# SAMA7D65D2GN8 register map
Vendor: Microchip Technology; Series: SAMA7D6; File version: 0
Registers are 32-bit, read-write, reset 0x0 unless marked. A register's access mark holds for its fields unless they carry their own. Offsets are from the block's base; [hi:lo] are bit positions; {n}, {i} and the like mark numbered series; 'fields as' and 'values as' point back to an identical list.

## SECUMOD — Security Module
Base 0xE0004000
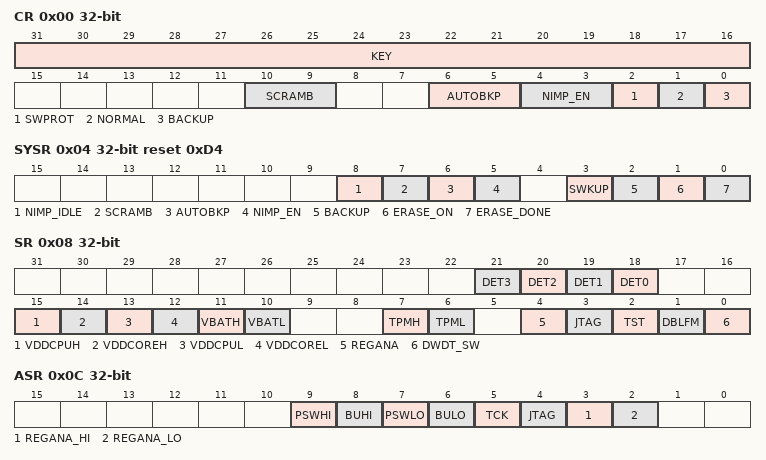
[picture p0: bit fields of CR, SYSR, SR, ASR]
0x00 CR wo — Control Register
  [31:16] KEY — Password
  [10:9] SCRAMB — Memory Scrambling Enable
    1=SCRAMB (Memories are scrambled (default).); 2=NO_SCRAMB (Memories are not scrambled.)
  [6:5] AUTOBKP — Automatic Normal to Backup Mode Switching
    1=AUTO_BCKP (When in Normal mode, the power-down of the core supply automatically switches to Backup mode simultaneously with core to backup isolation barrier activation (default).); 2=SW_BCKP (When in Normal mode, the software must switch to Backup mode before powering down the core.)
  [4:3] NIMP_EN — Non-Imprinting
    1=EN_NIMP (The non-imprinting mechanism is authorized to start when core power is off or bus reset is asserted); 2=DISABLED (The non-imprinting mechanism is disabled (default)); 3=EN_NIMP_IDLE (The non-imprinting mechanism is authorized to start when core power is off or bus reset is asserted or the CPU is idle)
  [2] SWPROT — Software Protection
    0=No effect; 1=Starts the BUSRAM4KB and BUREG256b Clear content
  [1] NORMAL — Normal Mode
    0=No effect; 1=Switches to Normal mode
  [0] BACKUP — Backup Mode
    0=No effect; 1=Switches to Backup mode
0x04 SYSR reset 0xD4 — System Status Register
  [8] NIMP_IDLE — 'CPU in Idle' Preliminary Condition for Non-Imprinting (RO)
    0=Idle is not part of the preliminary conditions list; 1=Idle is part of the preliminary conditions list
  [7] SCRAMB — Scrambling Enabled (RO)
    0=Disabled; 1=Enabled
  [6] AUTOBKP — Automatic Backup Mode Enabled (RO)
    0=Disabled; 1=Enabled
  [5] NIMP_EN — Non-Imprinting Enabled (RO)
    0=Disabled; 1=Enabled
  [3] SWKUP — SWKUP State (RO)
    0=No SWKUP signal sent since the last clear; 1=SWKUP signal has been sent since the last clear
  [2] BACKUP — Backup Mode (RO)
    0=Normal mode active; 1=Backup mode active
  [1] ERASE_ON — Erase Process Ongoing (RO)
    0=Erase automaton is not running; 1=Erase automaton is currently running, memories are not accessible
  [0] ERASE_DONE — Erasable Memories State (RW)
    0=Content of the secure memories has not been erased since the last clear; 1=Content of the secure memories has been erased since the last clear. Write a '1' to this bit to clear this flag. The flag also activates the SECURAM interrupt line as long as it is not cleared.
0x08 SR ro — Status Register
  [n+18] DET{n} (n=0..3) — PIOBUx Intrusion Detector
  [15] VDDCPUH — High VDDCPU Voltage Monitor
  [14] VDDCOREH — High VDDCORE Voltage Monitor
  [13] VDDCPUL — Low VDDCPU Voltage Monitor
  [12] VDDCOREL — Low VDDCORE Voltage Monitor
  [11] VBATH — High VBAT Voltage Monitor
  [10] VBATL — Low VBAT Voltage Monitor
  [7] TPMH — High Temperature Monitor
  [6] TPML — Low Temperature Monitor
  [4] REGANA — VDDANA Regulator Monitor
  [3] JTAG — Pins Monitor
  [2] TST — Test Pin Monitor
  [1] DBLFM — Double Frequency Monitor
  [0] DWDT_SW — Programmable Secure Watchdog Alarm
0x0C ASR ro — Auxiliary Status Register
  [9] PSWHI — VDDIN33 (used as secondary LDO power source through backup power switch) low alarm detected is the cause of VBATL flag in SECUMOD_SR
  [8] BUHI — VBAT high alarm detected is the cause of VBATH flag in SECUMOD_SR
  [7] PSWLO — VDDIN33 (used as secondary LDO power source through backup power switch) low alarm detected is the cause of VBATL flag in SECUMOD_SR
  [6] BULO — VBAT low alarm detected is the cause of VBATL flag in SECUMOD_SR
  [5] TCK — TCK/TMS activity detected is the cause of JTAG flag in SECUMOD_SR
  [4] JTAG — JTAGSEL or processor debug acknowledge is the cause of JTAG flag in SECUMOD_SR
  [3] REGANA_HI — High voltage alarm from VDDANA regulator is the cause of REGANA flag in SECUMOD_SR
  [2] REGANA_LO — Low voltage alarm from VDDANA regulator is the cause of REGANA flag in SECUMOD_SR
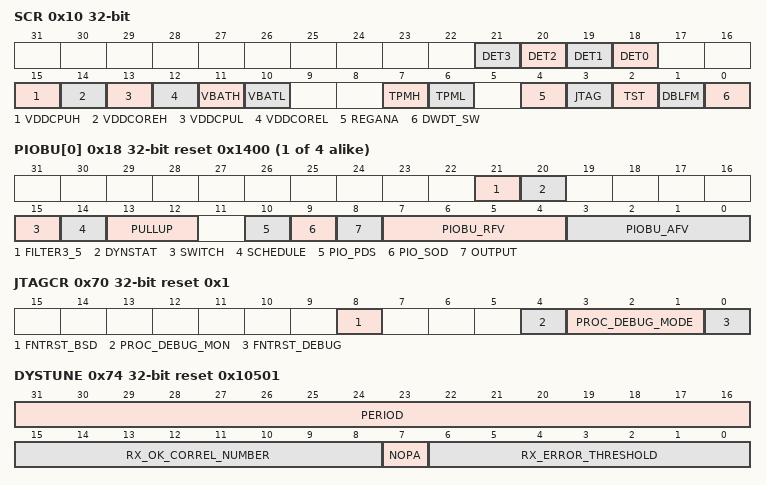
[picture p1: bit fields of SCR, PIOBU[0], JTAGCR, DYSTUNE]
0x10 SCR wo — Status Clear Register
  [n+18] DET{n} (n=0..3) — PIOBUx Intrusion Detector
  [15] VDDCPUH — High VDDCPU Voltage Monitor
  [14] VDDCOREH — High VDDCORE Voltage Monitor
  [13] VDDCPUL — Low VDDCPU Voltage Monitor
  [12] VDDCOREL — Low VDDCORE Voltage Monitor
  [11] VBATH — High VBAT Voltage Monitor
  [10] VBATL — Low VBAT Voltage Monitor
  [7] TPMH — High Temperature Monitor
  [6] TPML — Low Temperature Monitor
  [4] REGANA — VDDANA Regulator Monitor
  [3] JTAG — JTAG Pins Monitor
  [2] TST — Test Pin Monitor
  [1] DBLFM — Double Frequency Monitor
  [0] DWDT_SW — Programmable Secure Watchdog Alarm
0x14 RAMRDY ro — RAM Access Ready Register
  [0] READY — Ready for System Access Flag
{0x18+4i} PIOBU[{i}] (i=0..3) reset 0x1400 — PIO Backup Register x
  [21] FILTER3_5 — Filter for Dynamic Signatures Input
    0=3-stage majority vote (default); 1=5-stage majority vote
  [20] DYNSTAT — Switch for Static or Dynamic Detection Intrusion
    0=Static detection intrusion (default); 1=Dynamic detection intrusion
  [15] SWITCH — Switch State for Intrusion Detection
    0=Input default state is low level; 1=Input default state is high level
  [14] SCHEDULE — Pull-up/Down Scheduled
    0=Pull-up/pull-down is not scheduled; 1=Pull-up/pull-down is scheduled
  [13:12] PULLUP — Programmable Pull-up State
  [10] PIO_PDS — Level on the Pin in Input Mode (OUTPUT = 0) (Read-only)
    0=The I/O line is at level 0; 1=The I/O line is at level 1
  [9] PIO_SOD — Set/Clear the I/O Line when configured in Output Mode (OUTPUT =1)
    0=Clears the data to be driven on the I/O line; 1=Sets the data to be driven on the I/O line
  [8] OUTPUT — Configure I/O Line in Input/Output
    0=INPUT (I/O line is a pure input.); 1=OUTPUT (The I/O line is enabled in output.)
  [7:4] PIOBU_RFV — PIOBUx Reset Filter Value
    0=NO (0 (No static protection)); 1=MAX_2 (Maximum Counter Value: 2); 2=MAX_4 (Maximum Counter Value: 4); 3=MAX_8 (Maximum Counter Value: 8); 4=MAX_16 (Maximum Counter Value: 16); 5=MAX_32 (Maximum Counter Value: 32); 6=MAX_64 (Maximum Counter Value: 64); 7=MAX_128 (Maximum Counter Value: 128); 8=MAX_256 (Maximum Counter Value: 256); 9=MAX_512 (Maximum Counter Value: 512)
  [3:0] PIOBU_AFV — PIOBU Alarm Filter Value
    0=NO (0 (No static protection)); 1=MAX_2 (Maximum Counter Value before alarm: 2); 2=MAX_4 (Maximum Counter Value before alarm:4); 3=MAX_8 (Maximum Counter Value before alarm:8); 4=MAX_16 (Maximum Counter Value before alarm:16); 5=MAX_32 (Maximum Counter Value before alarm:32); 6=MAX_64 (Maximum Counter Value before alarm:64); 7=MAX_128 (Maximum Counter Value before alarm:128); 8=MAX_256 (Maximum Counter Value before alarm:256); 9=MAX_512 (Maximum Counter Value before alarm:512)
0x58 VBUFR reset 0x7 — VBAT Filter Register
  [2:0] VBATFV — VBAT Filter Value
0x64 VCOREFR reset 0x1FFF — VDDCORE Filter Register
  [12:0] VDDCORE_DBTV — VDDCORE Programmable Debouncing Time Value
0x68 VCPUFR reset 0x1FFF — VDDCPU Filter Register
  [12:0] VDDCPU_DBTV — VDDCPU Programmable Debouncing Time Value
0x70 JTAGCR reset 0x1 — JTAG Protection Control Register
  [8] FNTRST_BSD — Force Boundary JTAG NTRST
    0=Boundary JTAG are not blocked by the SECUMOD; 1=Boundary JTAG reset are held low, preventing Boundary JTAG to work
  [4] PROC_DEBUG_MON — Debug Acknowledge (DBGACK) Monitoring
    0=The Arm processor pin DBGACK is not monitored; as a consequence, the software can access debug features of the processor without causing an intrusion in the SECUMOD; 1=The Arm processor pin DBGACK is monitored. Processor entering in Debug mode triggers an intrusion
  [3:1] PROC_DEBUG_MODE — Invasive/Non-Invasive Secure/Non-Secure Debug Permissions
  [0] FNTRST_DEBUG — Force ARM Processor's TAP NTRST
    0=The ARM processor's TAP controller access is not blocked by the SECUMOD; 1=NDBGRESET of the ARM processor's TAP controller is held low, preventing the processor to switch to debug state
0x74 DYSTUNE reset 0x10501 — Dynamic Signature Tuning Register
  [31:16] PERIOD — Signature Clock Period
  [15:8] RX_OK_CORREL_NUMBER — Error Counter Reset Threshold
  [7] NOPA — No Periodic Alarm
    0=The alarm is regenerated periodically while intrusion is maintained; 1=The alarm is not regenerated periodically while intrusion is maintained
  [6:0] RX_ERROR_THRESHOLD — Error Detection Threshold
0x78 SCRKEY — Scrambling Key Register
  [31:0] SCRKEY — Scrambling Key Value
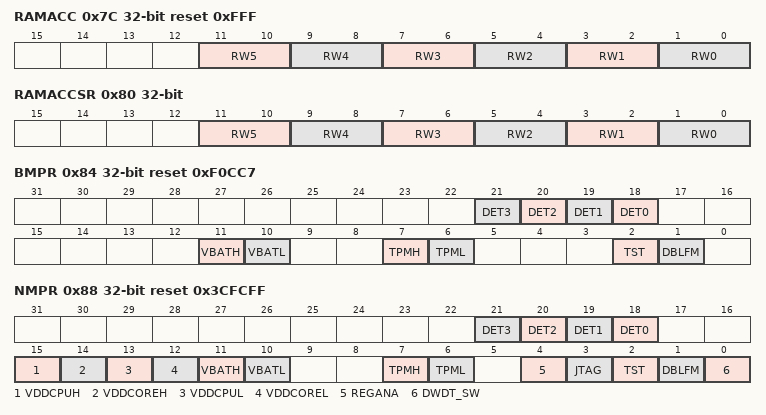
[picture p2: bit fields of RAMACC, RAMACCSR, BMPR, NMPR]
0x7C RAMACC reset 0xFFF — RAM Access Rights Register
  [11:10] RW5 — Access right for RAM region [5 Kbytes; 6 Kbytes] (register bank BUREG256b)
  [9:8] RW4 — Access right for RAM region [4 Kbytes; 5 Kbytes]
  [7:6] RW3 — Access right for RAM region [3 Kbytes; 4 Kbytes]
  [5:4] RW2 — Access right for RAM region [2 Kbytes; 3 Kbytes]
  [3:2] RW1 — Access right for RAM region [1 Kbyte; 2 Kbytes]
  [1:0] RW0 — Access right for RAM region [0; 1 Kbyte]
0x80 RAMACCSR — RAM Access Rights Status Register
  [11:10] RW5 — Access right status for RAM region [5 Kbytes; 6 Kbytes] (register bank BUREG256b)
  [9:8] RW4 — Access right status for RAM region [4 Kbytes; 5 Kbytes]
  [7:6] RW3 — Access right status for RAM region [3 Kbytes; 4 Kbytes]
  [5:4] RW2 — Access right status for RAM region [2 Kbytes; 3 Kbytes]
  [3:2] RW1 — Access right status for RAM region [1 Kbytes; 2 Kbytes]
  [1:0] RW0 — Access right status for RAM region [0; 1 Kbyte]
0x84 BMPR reset 0xF0CC7 — Backup Mode Protection Register
  [n+18] DET{n} (n=0..3) — PIOBUx Intrusion Detector
  [11] VBATH — High VBAT Voltage Monitor
  [10] VBATL — Low VBAT Voltage Monitor
  [7] TPMH — High Temperature Monitor
  [6] TPML — Low Temperature Monitor
  [2] TST — Test Pin Monitor
  [1] DBLFM — Double Frequency Monitor
0x88 NMPR reset 0x3CFCFF — Normal Mode Protection Register
  fields as SR
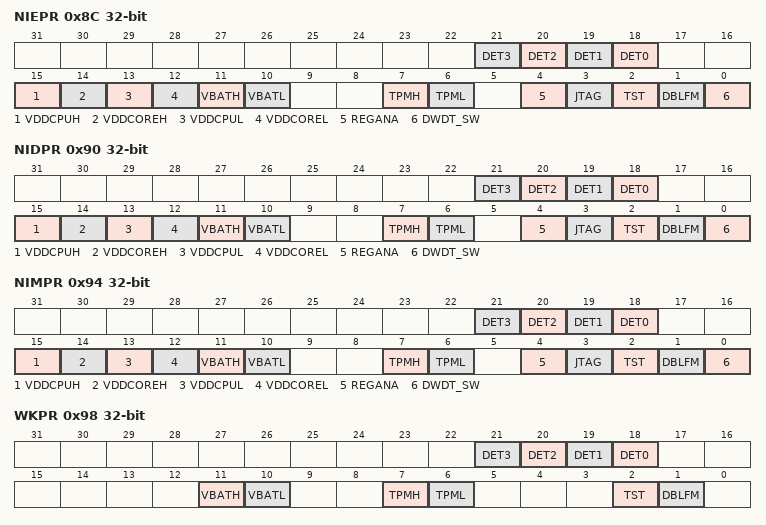
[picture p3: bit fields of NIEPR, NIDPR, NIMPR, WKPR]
0x8C NIEPR wo — Normal Interrupt Enable Protection Register
  [n+18] DET{n} (n=0..3) — PIOBU Intrusion Detector Protection Interrupt Enable
  [15] VDDCPUH — High VDDCPU Voltage Monitor Protection Interrupt Enable
  [14] VDDCOREH — High VDDCORE Voltage Monitor Protection Interrupt Enable
  [13] VDDCPUL — Low VDDCPU Voltage Monitor Protection Interrupt Enable
  [12] VDDCOREL — Low VDDCORE Voltage Monitor Protection Interrupt Enable
  [11] VBATH — High VBAT Voltage Monitor Protection Interrupt Enable
  [10] VBATL — Low VBAT Voltage Monitor Protection Interrupt Enable
  [7] TPMH — High Temperature Monitor Protection Interrupt Enable
  [6] TPML — Low Temperature Monitor Protection Interrupt Enable
  [4] REGANA — VDDANA Regulator Monitor Protection Interrupt Enable
  [3] JTAG — Pins Monitor Protection Interrupt Enable
  [2] TST — Test Pin Monitor Protection Interrupt Enable
  [1] DBLFM — Double Frequency Monitor Protection Interrupt Enable
  [0] DWDT_SW — Programmable Secure Watchdog Alarm Protection Interrupt Enable
0x90 NIDPR wo — Normal Interrupt Disable Protection Register
  [n+18] DET{n} (n=0..3) — PIOBU Intrusion Detector Protection Interrupt Disable
  [15] VDDCPUH — High VDDCPU Voltage Monitor Protection Interrupt Disable
  [14] VDDCOREH — High VDDCORE Voltage Monitor Protection Interrupt Disable
  [13] VDDCPUL — Low VDDCPU Voltage Monitor Protection Interrupt Disable
  [12] VDDCOREL — Low VDDCORE Voltage Monitor Protection Interrupt Disable
  [11] VBATH — High VBAT Voltage Monitor Protection Interrupt Disable
  [10] VBATL — Low VBAT Voltage Monitor Protection Interrupt Disable
  [7] TPMH — High Temperature Monitor Protection Interrupt Disable
  [6] TPML — Low Temperature Monitor Protection Interrupt Disable
  [4] REGANA — VDDANA Regulator Monitor Protection Interrupt Disable
  [3] JTAG — Pins Monitor Protection Interrupt Disable
  [2] TST — Test Pin Monitor Protection Interrupt Disable
  [1] DBLFM — Double Frequency Monitor Protection Interrupt Disable
  [0] DWDT_SW — Programmable Secure Watchdog Alarm Protection Interrupt Disable
0x94 NIMPR ro — Normal Interrupt Mask Protection Register
  [n+18] DET{n} (n=0..3) — PIOBU Intrusion Detector Protection Interrupt Mask
  [15] VDDCPUH — High VDDCPU Voltage Monitor Protection Interrupt Mask
  [14] VDDCOREH — High VDDCORE Voltage Monitor Protection Interrupt Mask
  [13] VDDCPUL — Low VDDCPU Voltage Monitor Protection Interrupt Mask
  [12] VDDCOREL — Low VDDCORE Voltage Monitor Protection Interrupt Mask
  [11] VBATH — High VBAT Voltage Monitor Protection Interrupt Mask
  [10] VBATL — Low VBAT Voltage Monitor Protection Interrupt Mask
  [7] TPMH — High Temperature Monitor Protection Interrupt Mask
  [6] TPML — Low Temperature Monitor Protection Interrupt Mask
  [4] REGANA — VDDANA Regulator Monitor Protection Interrupt Mask
  [3] JTAG — Pins Monitor Protection Interrupt Mask
  [2] TST — Test Pin Monitor Protection Interrupt Mask
  [1] DBLFM — Double Frequency Monitor Protection Interrupt Mask
  [0] DWDT_SW — Programmable Secure Watchdog Alarm Protection Interrupt Mask
0x98 WKPR — Wake-up Protection Register
  fields as BMPR
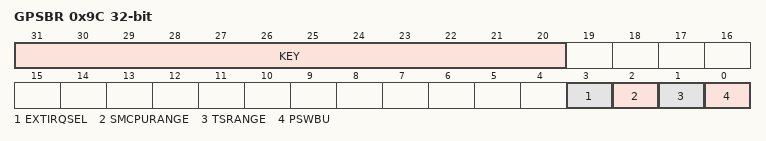
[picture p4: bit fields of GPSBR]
0x9C GPSBR — General Purpose Security Bits Register
  [31:20] KEY — Password
  [3] EXTIRQSEL — Interrupt Selection
    0=EXT_IRQ0; 1=EXT_IRQ1
  [2] SMCPURANGE — VDDCPU Supply Monitor Range
    0=Adjusts SM VDDCPU thresholds for 600 MHz max frequency operation; 1=Adjusts SM VDDCPU thresholds for 800 MHz max frequency operation
  [1] TSRANGE — Temperature Sensor Range
    0=Sets temperature sensor high threshold to 105 C; 1=Sets temperature sensor high threshold to 120 C
  [0] PSWBU — Power Source Switch Backup Domain
